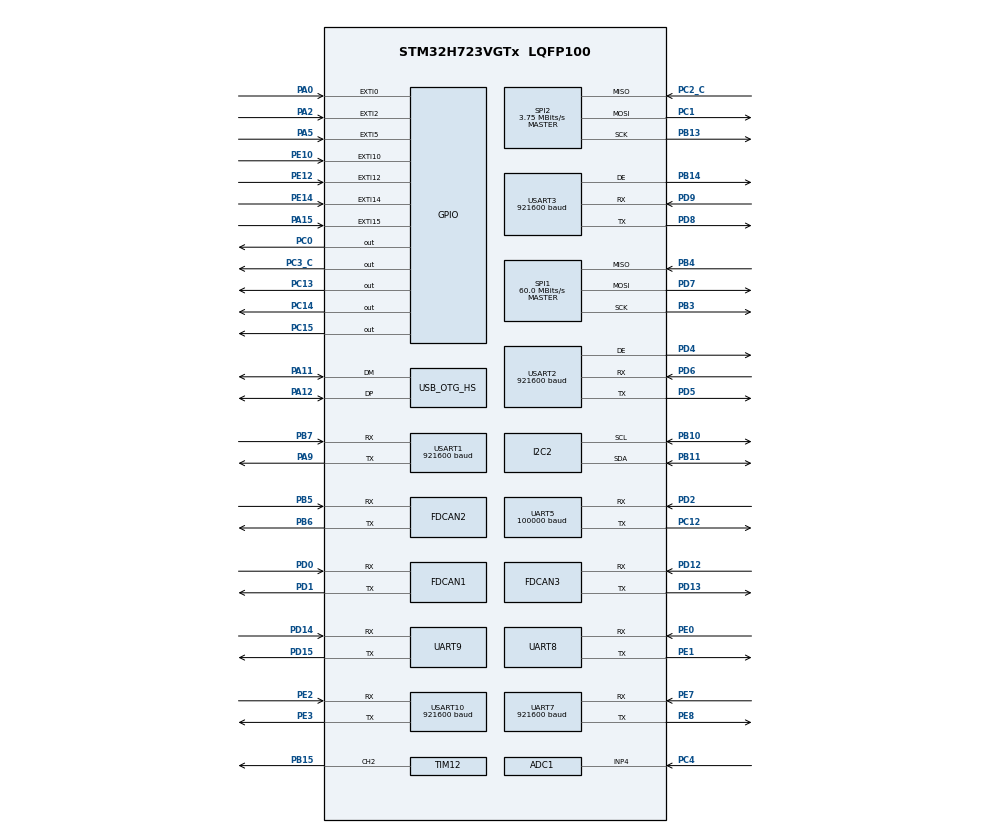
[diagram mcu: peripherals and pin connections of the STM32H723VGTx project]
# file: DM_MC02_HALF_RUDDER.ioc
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ADC1.Channel-0\#ChannelRegularConversion=ADC_CHANNEL_4
ADC1.ContinuousConvMode=ENABLE
ADC1.NbrOfConversionFlag=1
ADC1.OffsetNumber-0\#ChannelRegularConversion=ADC_OFFSET_NONE
ADC1.OffsetSignedSaturation-0\#ChannelRegularConversion=DISABLE
ADC1.Overrun=ADC_OVR_DATA_OVERWRITTEN
ADC1.Rank-0\#ChannelRegularConversion=1
ADC1.SamplingTime-0\#ChannelRegularConversion=ADC_SAMPLETIME_1CYCLE_5
ADC1.master=1
CORTEX_M7.CPU_DCache=Disabled
CORTEX_M7.CPU_ICache=Enabled
CORTEX_M7.default_mode_Activation=0
Dma.Request0=UART5_RX
Dma.Request1=SPI2_RX
Dma.Request10=USART2_TX
Dma.Request11=USART3_RX
Dma.Request12=USART3_TX
Dma.Request2=SPI2_TX
Dma.Request3=USART10_RX
Dma.Request4=USART10_TX
Dma.Request5=UART7_RX
Dma.Request6=UART7_TX
Dma.Request7=USART1_TX
Dma.Request8=USART1_RX
Dma.Request9=USART2_RX
Dma.SPI2_RX.1.Direction=DMA_PERIPH_TO_MEMORY
Dma.SPI2_RX.1.EventEnable=DISABLE
Dma.SPI2_RX.1.FIFOMode=DMA_FIFOMODE_DISABLE
Dma.SPI2_RX.1.Instance=DMA1_Stream2
Dma.SPI2_RX.1.MemDataAlignment=DMA_MDATAALIGN_BYTE
Dma.SPI2_RX.1.MemInc=DMA_MINC_ENABLE
Dma.SPI2_RX.1.Mode=DMA_NORMAL
Dma.SPI2_RX.1.PeriphDataAlignment=DMA_PDATAALIGN_BYTE
Dma.SPI2_RX.1.PeriphInc=DMA_PINC_DISABLE
Dma.SPI2_RX.1.Polarity=HAL_DMAMUX_REQ_GEN_RISING
Dma.SPI2_RX.1.Priority=DMA_PRIORITY_LOW
Dma.SPI2_RX.1.RequestNumber=1
Dma.SPI2_RX.1.SignalID=NONE
Dma.SPI2_RX.1.SyncEnable=DISABLE
Dma.SPI2_RX.1.SyncPolarity=HAL_DMAMUX_SYNC_NO_EVENT
Dma.SPI2_RX.1.SyncRequestNumber=1
Dma.SPI2_RX.1.SyncSignalID=NONE
Dma.SPI2_TX.2.Direction=DMA_MEMORY_TO_PERIPH
Dma.SPI2_TX.2.EventEnable=DISABLE
Dma.SPI2_TX.2.FIFOMode=DMA_FIFOMODE_DISABLE
Dma.SPI2_TX.2.Instance=DMA1_Stream3
Dma.SPI2_TX.2.MemDataAlignment=DMA_MDATAALIGN_BYTE
Dma.SPI2_TX.2.MemInc=DMA_MINC_ENABLE
Dma.SPI2_TX.2.Mode=DMA_NORMAL
Dma.SPI2_TX.2.PeriphDataAlignment=DMA_PDATAALIGN_BYTE
Dma.SPI2_TX.2.PeriphInc=DMA_PINC_DISABLE
Dma.SPI2_TX.2.Polarity=HAL_DMAMUX_REQ_GEN_RISING
Dma.SPI2_TX.2.Priority=DMA_PRIORITY_LOW
Dma.SPI2_TX.2.RequestNumber=1
Dma.SPI2_TX.2.SignalID=NONE
Dma.SPI2_TX.2.SyncEnable=DISABLE
Dma.SPI2_TX.2.SyncPolarity=HAL_DMAMUX_SYNC_NO_EVENT
Dma.SPI2_TX.2.SyncRequestNumber=1
Dma.SPI2_TX.2.SyncSignalID=NONE
Dma.UART5_RX.0.Direction=DMA_PERIPH_TO_MEMORY
Dma.UART5_RX.0.EventEnable=DISABLE
Dma.UART5_RX.0.FIFOMode=DMA_FIFOMODE_DISABLE
Dma.UART5_RX.0.Instance=DMA1_Stream1
Dma.UART5_RX.0.MemDataAlignment=DMA_MDATAALIGN_BYTE
Dma.UART5_RX.0.MemInc=DMA_MINC_ENABLE
Dma.UART5_RX.0.Mode=DMA_NORMAL
Dma.UART5_RX.0.PeriphDataAlignment=DMA_PDATAALIGN_BYTE
Dma.UART5_RX.0.PeriphInc=DMA_PINC_DISABLE
Dma.UART5_RX.0.Polarity=HAL_DMAMUX_REQ_GEN_RISING
Dma.UART5_RX.0.Priority=DMA_PRIORITY_LOW
Dma.UART5_RX.0.RequestNumber=1
Dma.UART5_RX.0.SignalID=NONE
Dma.UART5_RX.0.SyncEnable=DISABLE
Dma.UART5_RX.0.SyncPolarity=HAL_DMAMUX_SYNC_NO_EVENT
Dma.UART5_RX.0.SyncRequestNumber=1
Dma.UART5_RX.0.SyncSignalID=NONE
Dma.UART7_RX.5.Direction=DMA_PERIPH_TO_MEMORY
Dma.UART7_RX.5.EventEnable=DISABLE
Dma.UART7_RX.5.FIFOMode=DMA_FIFOMODE_DISABLE
Dma.UART7_RX.5.Instance=DMA1_Stream7
Dma.UART7_RX.5.MemDataAlignment=DMA_MDATAALIGN_BYTE
Dma.UART7_RX.5.MemInc=DMA_MINC_ENABLE
Dma.UART7_RX.5.Mode=DMA_NORMAL
Dma.UART7_RX.5.PeriphDataAlignment=DMA_PDATAALIGN_BYTE
Dma.UART7_RX.5.PeriphInc=DMA_PINC_DISABLE
Dma.UART7_RX.5.Polarity=HAL_DMAMUX_REQ_GEN_RISING
Dma.UART7_RX.5.Priority=DMA_PRIORITY_LOW
Dma.UART7_RX.5.RequestNumber=1
Dma.UART7_RX.5.SignalID=NONE
Dma.UART7_RX.5.SyncEnable=DISABLE
Dma.UART7_RX.5.SyncPolarity=HAL_DMAMUX_SYNC_NO_EVENT
Dma.UART7_RX.5.SyncRequestNumber=1
Dma.UART7_RX.5.SyncSignalID=NONE
Dma.UART7_TX.6.Direction=DMA_MEMORY_TO_PERIPH
Dma.UART7_TX.6.EventEnable=DISABLE
Dma.UART7_TX.6.FIFOMode=DMA_FIFOMODE_DISABLE
Dma.UART7_TX.6.Instance=DMA2_Stream0
Dma.UART7_TX.6.MemDataAlignment=DMA_MDATAALIGN_BYTE
Dma.UART7_TX.6.MemInc=DMA_MINC_ENABLE
Dma.UART7_TX.6.Mode=DMA_NORMAL
Dma.UART7_TX.6.PeriphDataAlignment=DMA_PDATAALIGN_BYTE
Dma.UART7_TX.6.PeriphInc=DMA_PINC_DISABLE
Dma.UART7_TX.6.Polarity=HAL_DMAMUX_REQ_GEN_RISING
Dma.UART7_TX.6.Priority=DMA_PRIORITY_LOW
Dma.UART7_TX.6.RequestNumber=1
Dma.UART7_TX.6.SignalID=NONE
Dma.UART7_TX.6.SyncEnable=DISABLE
Dma.UART7_TX.6.SyncPolarity=HAL_DMAMUX_SYNC_NO_EVENT
Dma.UART7_TX.6.SyncRequestNumber=1
Dma.UART7_TX.6.SyncSignalID=NONE
Dma.USART10_RX.3.Direction=DMA_PERIPH_TO_MEMORY
Dma.USART10_RX.3.EventEnable=DISABLE
Dma.USART10_RX.3.FIFOMode=DMA_FIFOMODE_DISABLE
Dma.USART10_RX.3.Instance=DMA1_Stream0
Dma.USART10_RX.3.MemDataAlignment=DMA_MDATAALIGN_BYTE
Dma.USART10_RX.3.MemInc=DMA_MINC_ENABLE
Dma.USART10_RX.3.Mode=DMA_NORMAL
Dma.USART10_RX.3.PeriphDataAlignment=DMA_PDATAALIGN_BYTE
Dma.USART10_RX.3.PeriphInc=DMA_PINC_DISABLE
Dma.USART10_RX.3.Polarity=HAL_DMAMUX_REQ_GEN_RISING
Dma.USART10_RX.3.Priority=DMA_PRIORITY_LOW
Dma.USART10_RX.3.RequestNumber=1
Dma.USART10_RX.3.SignalID=NONE
Dma.USART10_RX.3.SyncEnable=DISABLE
Dma.USART10_RX.3.SyncPolarity=HAL_DMAMUX_SYNC_NO_EVENT
Dma.USART10_RX.3.SyncRequestNumber=1
Dma.USART10_RX.3.SyncSignalID=NONE
Dma.USART10_TX.4.Direction=DMA_MEMORY_TO_PERIPH
Dma.USART10_TX.4.EventEnable=DISABLE
Dma.USART10_TX.4.FIFOMode=DMA_FIFOMODE_DISABLE
Dma.USART10_TX.4.Instance=DMA1_Stream4
Dma.USART10_TX.4.MemDataAlignment=DMA_MDATAALIGN_BYTE
Dma.USART10_TX.4.MemInc=DMA_MINC_ENABLE
Dma.USART10_TX.4.Mode=DMA_NORMAL
Dma.USART10_TX.4.PeriphDataAlignment=DMA_PDATAALIGN_BYTE
Dma.USART10_TX.4.PeriphInc=DMA_PINC_DISABLE
Dma.USART10_TX.4.Polarity=HAL_DMAMUX_REQ_GEN_RISING
Dma.USART10_TX.4.Priority=DMA_PRIORITY_LOW
Dma.USART10_TX.4.RequestNumber=1
Dma.USART10_TX.4.SignalID=NONE
Dma.USART10_TX.4.SyncEnable=DISABLE
Dma.USART10_TX.4.SyncPolarity=HAL_DMAMUX_SYNC_NO_EVENT
Dma.USART10_TX.4.SyncRequestNumber=1
Dma.USART10_TX.4.SyncSignalID=NONE
Dma.USART1_RX.8.Direction=DMA_PERIPH_TO_MEMORY
Dma.USART1_RX.8.EventEnable=DISABLE
Dma.USART1_RX.8.FIFOMode=DMA_FIFOMODE_DISABLE
Dma.USART1_RX.8.Instance=DMA1_Stream6
Dma.USART1_RX.8.MemDataAlignment=DMA_MDATAALIGN_BYTE
Dma.USART1_RX.8.MemInc=DMA_MINC_ENABLE
Dma.USART1_RX.8.Mode=DMA_NORMAL
Dma.USART1_RX.8.PeriphDataAlignment=DMA_PDATAALIGN_BYTE
Dma.USART1_RX.8.PeriphInc=DMA_PINC_DISABLE
Dma.USART1_RX.8.Polarity=HAL_DMAMUX_REQ_GEN_RISING
Dma.USART1_RX.8.Priority=DMA_PRIORITY_LOW
Dma.USART1_RX.8.RequestNumber=1
Dma.USART1_RX.8.SignalID=NONE
Dma.USART1_RX.8.SyncEnable=DISABLE
Dma.USART1_RX.8.SyncPolarity=HAL_DMAMUX_SYNC_NO_EVENT
Dma.USART1_RX.8.SyncRequestNumber=1
Dma.USART1_RX.8.SyncSignalID=NONE
Dma.USART1_TX.7.Direction=DMA_MEMORY_TO_PERIPH
Dma.USART1_TX.7.EventEnable=DISABLE
Dma.USART1_TX.7.FIFOMode=DMA_FIFOMODE_DISABLE
Dma.USART1_TX.7.Instance=DMA1_Stream5
Dma.USART1_TX.7.MemDataAlignment=DMA_MDATAALIGN_BYTE
Dma.USART1_TX.7.MemInc=DMA_MINC_ENABLE
Dma.USART1_TX.7.Mode=DMA_NORMAL
Dma.USART1_TX.7.PeriphDataAlignment=DMA_PDATAALIGN_BYTE
Dma.USART1_TX.7.PeriphInc=DMA_PINC_DISABLE
Dma.USART1_TX.7.Polarity=HAL_DMAMUX_REQ_GEN_RISING
Dma.USART1_TX.7.Priority=DMA_PRIORITY_LOW
Dma.USART1_TX.7.RequestNumber=1
Dma.USART1_TX.7.SignalID=NONE
Dma.USART1_TX.7.SyncEnable=DISABLE
Dma.USART1_TX.7.SyncPolarity=HAL_DMAMUX_SYNC_NO_EVENT
Dma.USART1_TX.7.SyncRequestNumber=1
Dma.USART1_TX.7.SyncSignalID=NONE
Dma.USART2_RX.9.Direction=DMA_PERIPH_TO_MEMORY
Dma.USART2_RX.9.EventEnable=DISABLE
Dma.USART2_RX.9.FIFOMode=DMA_FIFOMODE_DISABLE
Dma.USART2_RX.9.Instance=DMA2_Stream1
Dma.USART2_RX.9.MemDataAlignment=DMA_MDATAALIGN_BYTE
Dma.USART2_RX.9.MemInc=DMA_MINC_ENABLE
Dma.USART2_RX.9.Mode=DMA_NORMAL
Dma.USART2_RX.9.PeriphDataAlignment=DMA_PDATAALIGN_BYTE
Dma.USART2_RX.9.PeriphInc=DMA_PINC_DISABLE
Dma.USART2_RX.9.Polarity=HAL_DMAMUX_REQ_GEN_RISING
Dma.USART2_RX.9.Priority=DMA_PRIORITY_LOW
Dma.USART2_RX.9.RequestNumber=1
Dma.USART2_RX.9.SignalID=NONE
Dma.USART2_RX.9.SyncEnable=DISABLE
Dma.USART2_RX.9.SyncPolarity=HAL_DMAMUX_SYNC_NO_EVENT
Dma.USART2_RX.9.SyncRequestNumber=1
Dma.USART2_RX.9.SyncSignalID=NONE
Dma.USART2_TX.10.Direction=DMA_MEMORY_TO_PERIPH
Dma.USART2_TX.10.EventEnable=DISABLE
Dma.USART2_TX.10.FIFOMode=DMA_FIFOMODE_DISABLE
Dma.USART2_TX.10.Instance=DMA2_Stream2
Dma.USART2_TX.10.MemDataAlignment=DMA_MDATAALIGN_BYTE
Dma.USART2_TX.10.MemInc=DMA_MINC_ENABLE
Dma.USART2_TX.10.Mode=DMA_NORMAL
Dma.USART2_TX.10.PeriphDataAlignment=DMA_PDATAALIGN_BYTE
Dma.USART2_TX.10.PeriphInc=DMA_PINC_DISABLE
Dma.USART2_TX.10.Polarity=HAL_DMAMUX_REQ_GEN_RISING
Dma.USART2_TX.10.Priority=DMA_PRIORITY_LOW
Dma.USART2_TX.10.RequestNumber=1
Dma.USART2_TX.10.SignalID=NONE
Dma.USART2_TX.10.SyncEnable=DISABLE
Dma.USART2_TX.10.SyncPolarity=HAL_DMAMUX_SYNC_NO_EVENT
Dma.USART2_TX.10.SyncRequestNumber=1
Dma.USART2_TX.10.SyncSignalID=NONE
Dma.USART3_RX.11.Direction=DMA_PERIPH_TO_MEMORY
Dma.USART3_RX.11.EventEnable=DISABLE
Dma.USART3_RX.11.FIFOMode=DMA_FIFOMODE_DISABLE
Dma.USART3_RX.11.Instance=DMA2_Stream3
Dma.USART3_RX.11.MemDataAlignment=DMA_MDATAALIGN_BYTE
Dma.USART3_RX.11.MemInc=DMA_MINC_ENABLE
Dma.USART3_RX.11.Mode=DMA_NORMAL
Dma.USART3_RX.11.PeriphDataAlignment=DMA_PDATAALIGN_BYTE
Dma.USART3_RX.11.PeriphInc=DMA_PINC_DISABLE
Dma.USART3_RX.11.Polarity=HAL_DMAMUX_REQ_GEN_RISING
Dma.USART3_RX.11.Priority=DMA_PRIORITY_LOW
Dma.USART3_RX.11.RequestNumber=1
Dma.USART3_RX.11.SignalID=NONE
Dma.USART3_RX.11.SyncEnable=DISABLE
Dma.USART3_RX.11.SyncPolarity=HAL_DMAMUX_SYNC_NO_EVENT
Dma.USART3_RX.11.SyncRequestNumber=1
Dma.USART3_RX.11.SyncSignalID=NONE
Dma.USART3_TX.12.Direction=DMA_MEMORY_TO_PERIPH
Dma.USART3_TX.12.EventEnable=DISABLE
Dma.USART3_TX.12.FIFOMode=DMA_FIFOMODE_DISABLE
Dma.USART3_TX.12.Instance=DMA2_Stream4
Dma.USART3_TX.12.MemDataAlignment=DMA_MDATAALIGN_BYTE
Dma.USART3_TX.12.MemInc=DMA_MINC_ENABLE
Dma.USART3_TX.12.Mode=DMA_NORMAL
Dma.USART3_TX.12.PeriphDataAlignment=DMA_PDATAALIGN_BYTE
Dma.USART3_TX.12.PeriphInc=DMA_PINC_DISABLE
Dma.USART3_TX.12.Polarity=HAL_DMAMUX_REQ_GEN_RISING
Dma.USART3_TX.12.Priority=DMA_PRIORITY_LOW
Dma.USART3_TX.12.RequestNumber=1
Dma.USART3_TX.12.SignalID=NONE
Dma.USART3_TX.12.SyncEnable=DISABLE
Dma.USART3_TX.12.SyncPolarity=HAL_DMAMUX_SYNC_NO_EVENT
Dma.USART3_TX.12.SyncRequestNumber=1
Dma.USART3_TX.12.SyncSignalID=NONE
FDCAN1.AutoRetransmission=ENABLE
FDCAN1.CalculateBaudRateNominal=1000000
FDCAN1.CalculateTimeBitNominal=1000
FDCAN1.CalculateTimeQuantumNominal=100.0
FDCAN1.DataTimeSeg1=12
FDCAN1.DataTimeSeg2=2
FDCAN1.ExtFiltersNbr=0
FDCAN1.FrameFormat=FDCAN_FRAME_FD_BRS
FDCAN1.Mode=FDCAN_MODE_NORMAL
FDCAN1.NominalPrescaler=12
FDCAN1.NominalTimeSeg1=7
FDCAN1.NominalTimeSeg2=2
FDCAN1.ProtocolException=ENABLE
FDCAN1.RxBufferSize=FDCAN_DATA_BYTES_64
FDCAN1.RxBuffersNbr=0
FDCAN1.RxFifo0ElmtSize=FDCAN_DATA_BYTES_64
FDCAN1.RxFifo0ElmtsNbr=8
FDCAN1.RxFifo1ElmtSize=FDCAN_DATA_BYTES_64
FDCAN1.RxFifo1ElmtsNbr=0
FDCAN1.StdFiltersNbr=0
FDCAN1.TxBuffersNbr=0
FDCAN1.TxElmtSize=FDCAN_DATA_BYTES_64
FDCAN1.TxEventsNbr=32
FDCAN1.TxFifoQueueElmtsNbr=32
FDCAN2.AutoRetransmission=ENABLE
FDCAN2.CalculateBaudRateNominal=1000000
FDCAN2.CalculateTimeBitNominal=1000
FDCAN2.CalculateTimeQuantumNominal=100.0
FDCAN2.DataTimeSeg1=12
FDCAN2.DataTimeSeg2=2
FDCAN2.ExtFiltersNbr=0
FDCAN2.FrameFormat=FDCAN_FRAME_FD_BRS
FDCAN2.MessageRAMOffset=784
FDCAN2.NominalPrescaler=12
FDCAN2.NominalTimeSeg1=7
FDCAN2.NominalTimeSeg2=2
FDCAN2.ProtocolException=ENABLE
FDCAN2.RxBufferSize=FDCAN_DATA_BYTES_64
FDCAN2.RxFifo0ElmtSize=FDCAN_DATA_BYTES_64
FDCAN2.RxFifo0ElmtsNbr=8
FDCAN2.RxFifo1ElmtSize=FDCAN_DATA_BYTES_64
FDCAN2.RxFifo1ElmtsNbr=0
FDCAN2.StdFiltersNbr=0
FDCAN2.TxBuffersNbr=0
FDCAN2.TxElmtSize=FDCAN_DATA_BYTES_64
FDCAN2.TxEventsNbr=32
FDCAN2.TxFifoQueueElmtsNbr=32
FDCAN3.AutoRetransmission=ENABLE
FDCAN3.CalculateBaudRateNominal=1000000
FDCAN3.CalculateTimeBitNominal=1000
FDCAN3.CalculateTimeQuantumNominal=100.0
FDCAN3.DataPrescaler=1
FDCAN3.DataTimeSeg1=12
FDCAN3.DataTimeSeg2=2
FDCAN3.ExtFiltersNbr=0
FDCAN3.FrameFormat=FDCAN_FRAME_FD_BRS
FDCAN3.MessageRAMOffset=1568
FDCAN3.NominalPrescaler=12
FDCAN3.NominalTimeSeg1=7
FDCAN3.NominalTimeSeg2=2
FDCAN3.ProtocolException=ENABLE
FDCAN3.RxBufferSize=FDCAN_DATA_BYTES_64
FDCAN3.RxFifo0ElmtSize=FDCAN_DATA_BYTES_64
FDCAN3.RxFifo0ElmtsNbr=8
FDCAN3.RxFifo1ElmtSize=FDCAN_DATA_BYTES_64
FDCAN3.RxFifo1ElmtsNbr=0
FDCAN3.StdFiltersNbr=0
FDCAN3.TxBuffersNbr=0
FDCAN3.TxElmtSize=FDCAN_DATA_BYTES_64
FDCAN3.TxEventsNbr=32
FDCAN3.TxFifoQueueElmtsNbr=32
FREERTOS.INCLUDE_eTaskGetState=1
FREERTOS.INCLUDE_pcTaskGetTaskName=1
FREERTOS.INCLUDE_uxTaskGetStackHighWaterMark=1
FREERTOS.INCLUDE_uxTaskGetStackHighWaterMark2=1
FREERTOS.INCLUDE_vTaskCleanUpResources=1
FREERTOS.INCLUDE_vTaskDelayUntil=1
FREERTOS.INCLUDE_xQueueGetMutexHolder=1
FREERTOS.INCLUDE_xSemaphoreGetMutexHolder=1
FREERTOS.INCLUDE_xTaskAbortDelay=1
FREERTOS.INCLUDE_xTaskGetCurrentTaskHandle=1
FREERTOS.INCLUDE_xTaskGetHandle=1
FREERTOS.MEMORY_ALLOCATION=1
FREERTOS.Tasks01=defaultTask,-3,128,StartDefaultTask,Default,NULL,Static,defaultTaskBuffer,defaultTaskControlBlock
FREERTOS.configCHECK_FOR_STACK_OVERFLOW=2
FREERTOS.configENABLE_BACKWARD_COMPATIBILITY=0
FREERTOS.configENABLE_FPU=1
FREERTOS.configGENERATE_RUN_TIME_STATS=1
FREERTOS.configRECORD_STACK_HIGH_ADDRESS=1
FREERTOS.configUSE_APPLICATION_TASK_TAG=1
FREERTOS.configUSE_COUNTING_SEMAPHORES=1
FREERTOS.configUSE_IDLE_HOOK=1
FREERTOS.configUSE_RECURSIVE_MUTEXES=1
FREERTOS.configUSE_TICK_HOOK=1
FREERTOS.configUSE_TRACE_FACILITY=1
I2C2.Timing=0x307075B1
Mcu.Family=STM32H7
Mcu.Name=STM32H723VGTx
Mcu.Package=LQFP100
NVIC.DMA1_Stream0_IRQn=true\:5\:0\:false\:false\:true\:true\:false\:true\:true
NVIC.DMA1_Stream1_IRQn=true\:5\:0\:false\:false\:true\:true\:false\:true\:true
NVIC.DMA1_Stream2_IRQn=true\:5\:0\:false\:false\:true\:true\:false\:true\:true
NVIC.DMA1_Stream3_IRQn=true\:5\:0\:false\:false\:true\:true\:false\:true\:true
NVIC.DMA1_Stream4_IRQn=true\:5\:0\:false\:false\:true\:true\:false\:true\:true
NVIC.DMA1_Stream5_IRQn=true\:5\:0\:false\:false\:true\:true\:false\:true\:true
NVIC.DMA1_Stream6_IRQn=true\:5\:0\:false\:false\:true\:true\:false\:true\:true
NVIC.DMA1_Stream7_IRQn=true\:5\:0\:false\:false\:true\:true\:false\:true\:true
NVIC.DMA2_Stream0_IRQn=true\:5\:0\:false\:false\:true\:true\:false\:true\:true
NVIC.DMA2_Stream1_IRQn=true\:5\:0\:false\:false\:true\:true\:false\:true\:true
NVIC.DMA2_Stream2_IRQn=true\:5\:0\:false\:false\:true\:true\:false\:true\:true
NVIC.DMA2_Stream3_IRQn=true\:5\:0\:false\:false\:true\:true\:false\:true\:true
NVIC.DMA2_Stream4_IRQn=true\:5\:0\:false\:false\:true\:true\:false\:true\:true
NVIC.EXTI0_IRQn=true\:5\:0\:false\:false\:true\:true\:true\:true\:true
NVIC.EXTI15_10_IRQn=true\:5\:0\:false\:false\:true\:true\:true\:true\:true
NVIC.EXTI2_IRQn=true\:5\:0\:false\:false\:true\:true\:true\:true\:true
NVIC.EXTI9_5_IRQn=true\:5\:0\:false\:false\:true\:true\:true\:true\:true
NVIC.FDCAN1_IT0_IRQn=true\:5\:0\:false\:false\:true\:true\:true\:true\:true
NVIC.FDCAN1_IT1_IRQn=true\:5\:0\:false\:false\:true\:true\:true\:true\:true
NVIC.FDCAN2_IT0_IRQn=true\:5\:0\:false\:false\:true\:true\:true\:true\:true
NVIC.FDCAN2_IT1_IRQn=true\:5\:0\:false\:false\:true\:true\:true\:true\:true
NVIC.FDCAN3_IT0_IRQn=true\:5\:0\:false\:false\:true\:true\:true\:true\:true
NVIC.FDCAN3_IT1_IRQn=true\:5\:0\:false\:false\:true\:true\:true\:true\:true
NVIC.OTG_HS_EP1_IN_IRQn=true\:5\:0\:false\:false\:true\:true\:true\:true\:true
NVIC.OTG_HS_EP1_OUT_IRQn=true\:5\:0\:false\:false\:true\:true\:true\:true\:true
NVIC.OTG_HS_IRQn=true\:5\:0\:false\:false\:true\:true\:true\:true\:true
NVIC.PriorityGroup=NVIC_PRIORITYGROUP_4
NVIC.SPI2_IRQn=true\:5\:0\:false\:false\:true\:true\:false\:true\:true
NVIC.TIM23_IRQn=true\:15\:0\:false\:false\:true\:false\:false\:true\:true
NVIC.TimeBase=TIM23_IRQn
NVIC.TimeBaseIP=TIM23
NVIC.UART5_IRQn=true\:5\:0\:false\:false\:true\:true\:false\:true\:true
NVIC.UART7_IRQn=true\:5\:0\:false\:false\:true\:true\:true\:true\:true
NVIC.USART10_IRQn=true\:5\:0\:false\:false\:true\:true\:true\:true\:true
NVIC.USART1_IRQn=true\:5\:0\:false\:false\:true\:true\:true\:true\:true
NVIC.USART2_IRQn=true\:5\:0\:false\:false\:true\:true\:true\:true\:true
NVIC.USART3_IRQn=true\:5\:0\:false\:false\:true\:true\:true\:true\:true
PA0.Signal=GPXTI0
PA11.Mode=Device_Only_FS
PA11.Signal=USB_OTG_HS_DM
PA12.Mode=Device_Only_FS
PA12.Signal=USB_OTG_HS_DP
PA13(JTMS/SWDIO).Mode=Serial_Wire
PA13(JTMS/SWDIO).Signal=DEBUG_JTMS-SWDIO
PA14(JTCK/SWCLK).Mode=Serial_Wire
PA14(JTCK/SWCLK).Signal=DEBUG_JTCK-SWCLK
PA15(JTDI).Signal=GPXTI15
PA2.Signal=GPXTI2
PA5.Signal=GPXTI5
PA9.Mode=Asynchronous
PA9.Signal=USART1_TX
PB10.Mode=I2C
PB10.Signal=I2C2_SCL
PB11.Mode=I2C
PB11.Signal=I2C2_SDA
PB13.GPIO_Speed=GPIO_SPEED_FREQ_VERY_HIGH
PB13.Mode=Full_Duplex_Master
PB13.Signal=SPI2_SCK
PB14.Mode=Hardware Flow Control (RS485)
PB14.Signal=USART3_DE
PB15.Signal=S_TIM12_CH2
PB3(JTDO/TRACESWO).Mode=Full_Duplex_Master
PB3(JTDO/TRACESWO).Signal=SPI1_SCK
PB4(NJTRST).Mode=Full_Duplex_Master
PB4(NJTRST).Signal=SPI1_MISO
PB5.Mode=FDCAN_Activate
PB5.Signal=FDCAN2_RX
PB6.Mode=FDCAN_Activate
PB6.Signal=FDCAN2_TX
PB7.Mode=Asynchronous
PB7.Signal=USART1_RX
PC0.GPIO_Speed=GPIO_SPEED_FREQ_VERY_HIGH
PC0.PinState=GPIO_PIN_SET
PC0.Signal=GPIO_Output
PC1.GPIO_Speed=GPIO_SPEED_FREQ_VERY_HIGH
PC1.Mode=Full_Duplex_Master
PC1.Signal=SPI2_MOSI
PC12.Mode=Asynchronous
PC12.Signal=UART5_TX
PC13.Signal=GPIO_Output
PC14-OSC32_IN.Signal=GPIO_Output
PC15-OSC32_OUT.Signal=GPIO_Output
PC2_C.GPIO_Speed=GPIO_SPEED_FREQ_VERY_HIGH
PC2_C.Mode=Full_Duplex_Master
PC2_C.Signal=SPI2_MISO
PC3_C.GPIO_Speed=GPIO_SPEED_FREQ_VERY_HIGH
PC3_C.PinState=GPIO_PIN_SET
PC3_C.Signal=GPIO_Output
PC4.Signal=ADCx_INP4
PD0.Mode=FDCAN_Activate
PD0.Signal=FDCAN1_RX
PD1.Mode=FDCAN_Activate
PD1.Signal=FDCAN1_TX
PD12.Mode=FDCAN_Activate
PD12.Signal=FDCAN3_RX
PD13.Mode=FDCAN_Activate
PD13.Signal=FDCAN3_TX
PD14.Mode=Asynchronous
PD14.Signal=UART9_RX
PD15.Mode=Asynchronous
PD15.Signal=UART9_TX
PD2.Mode=Asynchronous
PD2.Signal=UART5_RX
PD4.Mode=Hardware Flow Control (RS485)
PD4.Signal=USART2_DE
PD5.Mode=Asynchronous
PD5.Signal=USART2_TX
PD6.Mode=Asynchronous
PD6.Signal=USART2_RX
PD7.Mode=Full_Duplex_Master
PD7.Signal=SPI1_MOSI
PD8.Mode=Asynchronous
PD8.Signal=USART3_TX
PD9.Mode=Asynchronous
PD9.Signal=USART3_RX
PE0.Mode=Asynchronous
PE0.Signal=UART8_RX
PE1.Mode=Asynchronous
PE1.Signal=UART8_TX
PE10.Signal=GPXTI10
PE12.Signal=GPXTI12
PE13.Signal=S_TIM1_CH3
PE14.Signal=GPXTI14
PE2.Mode=Asynchronous
PE2.Signal=USART10_RX
PE3.Mode=Asynchronous
PE3.Signal=USART10_TX
PE7.Mode=Asynchronous
PE7.Signal=UART7_RX
PE8.Mode=Asynchronous
PE8.Signal=UART7_TX
PE9.Signal=S_TIM1_CH1
PH0-OSC_IN.Mode=HSE-External-Oscillator
PH0-OSC_IN.Signal=RCC_OSC_IN
PH1-OSC_OUT.Mode=HSE-External-Oscillator
PH1-OSC_OUT.Signal=RCC_OSC_OUT
ProjectManager.HeapSize=0x200
ProjectManager.StackSize=0x400
ProjectManager.TargetToolchain=CMake
RCC.ADCFreq_Value=96000000
RCC.APB1Freq_Value=120000000
RCC.APB2Freq_Value=120000000
RCC.APB3Freq_Value=120000000
RCC.APB4Freq_Value=120000000
RCC.CortexFreq_Value=480000000
RCC.D1PPRE=RCC_APB3_DIV2
RCC.D2PPRE1=RCC_APB1_DIV2
RCC.D2PPRE2=RCC_APB2_DIV2
RCC.D3PPRE=RCC_APB4_DIV2
RCC.DIVM1=2
RCC.DIVM2=2
RCC.DIVM3=2
RCC.DIVN1=40
RCC.DIVN2=16
RCC.DIVN3=16
RCC.DIVP1=1
RCC.DIVQ1=4
RCC.DIVQ3=4
RCC.HCLKFreq_Value=240000000
RCC.HPRE=RCC_HCLK_DIV2
RCC.HSE_VALUE=24000000
RCC.PLL1_VCO_SEL-AdvancedSettings=RCC_PLL1VCOMEDIUM
RCC.PLL2FRACN=0
RCC.PLL3FRACN=0
RCC.PLL3_VCI_Range-AdvancedSettings=RCC_PLL3VCIRANGE_3
RCC.PLL3_VCO_SEL-AdvancedSettings=RCC_PLL3VCOMEDIUM
RCC.PLLFRACN=0
RCC.PLLSourceVirtual=RCC_PLLSOURCE_HSE
RCC.SYSCLKFreq_VALUE=480000000
RCC.SYSCLKSource=RCC_SYSCLKSOURCE_PLLCLK
RCC.USBCLockSelection=RCC_USBCLKSOURCE_PLL3
RCC.USBFreq_Value=48000000
SH.ADCx_INP4.0=ADC1_INP4,IN4-Single-Ended
SH.S_TIM12_CH2.0=TIM12_CH2,PWM Generation2 CH2
SH.S_TIM1_CH1.0=TIM1_CH1
SH.S_TIM1_CH3.0=TIM1_CH3
SPI1.CalculateBaudRate=60.0 MBits/s
SPI1.Direction=SPI_DIRECTION_2LINES
SPI1.Mode=SPI_MODE_MASTER
SPI1.VirtualType=VM_MASTER
SPI2.BaudRatePrescaler=SPI_BAUDRATEPRESCALER_32
SPI2.CLKPhase=SPI_PHASE_2EDGE
SPI2.CLKPolarity=SPI_POLARITY_HIGH
SPI2.CalculateBaudRate=3.75 MBits/s
SPI2.DataSize=SPI_DATASIZE_8BIT
SPI2.Direction=SPI_DIRECTION_2LINES
SPI2.Mode=SPI_MODE_MASTER
SPI2.NSSPMode=SPI_NSS_PULSE_DISABLE
SPI2.VirtualType=VM_MASTER
TIM12.Channel-PWM\ Generation2\ CH2=TIM_CHANNEL_2
TIM12.Period=60000
TIM12.Prescaler=1-1
TIM2.Period=60000
TIM2.Prescaler=80-1
UART5.BaudRate=100000
UART5.Mode=MODE_RX
UART5.Parity=PARITY_EVEN
UART5.StopBits=UART_STOPBITS_2
UART5.WordLength=WORDLENGTH_9B
UART7.BaudRate=921600
USART1.BaudRate=921600
USART1.Mode=MODE_TX_RX
USART1.VirtualMode-Asynchronous=VM_ASYNC
USART10.BaudRate=921600
USART10.VirtualMode=VM_ASYNC
USART2.BaudRate=921600
USART2.VirtualMode-Asynchronous=VM_ASYNC
USART2.VirtualMode-Hardware\ Flow\ Control\ (RS485)=VM_ASYNC
USART3.BaudRate=921600
USART3.VirtualMode-Asynchronous=VM_ASYNC
USART3.VirtualMode-Hardware\ Flow\ Control\ (RS485)=VM_ASYNC
USB_DEVICE.CLASS_NAME_HS=CDC
USB_DEVICE.PRODUCT_STRING_CDC_HS=BetaRobot_VCP
USB_DEVICE.USBD_LPM_ENABLED=0
USB_DEVICE.VirtualMode=Cdc
USB_DEVICE.VirtualModeHS=Cdc_HS
USB_OTG_HS.VirtualMode-Device_Only_FS=Device_Only_FS
USB_OTG_HS.dma_enable-Device_Only_FS=DISABLE
VP_FREERTOS_VS_CMSIS_V1.Mode=CMSIS_V1
VP_MEMORYMAP_VS_MEMORYMAP.Mode=CurAppReg
VP_SYS_VS_tim23.Mode=TIM23
VP_TIM12_VS_ClockSourceINT.Mode=Internal
VP_TIM1_VS_ClockSourceINT.Mode=Internal
VP_TIM2_VS_ClockSourceINT.Mode=Internal
VP_USB_DEVICE_VS_USB_DEVICE_CDC_HS.Mode=CDC_HS
board=custom

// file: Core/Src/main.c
/* USER CODE BEGIN Header */
/**
  ******************************************************************************
  * @file           : main.c
  * @brief          : Main program body
  ******************************************************************************
  * @attention
  *
  * Copyright (c) 2026 STMicroelectronics.
  * All rights reserved.
  *
  * This software is licensed under terms that can be found in the LICENSE file
  * in the root directory of this software component.
  * If no LICENSE file comes with this software, it is provided AS-IS.
  *
  ******************************************************************************
  */
/* USER CODE END Header */
#include "main.h"
#include "cmsis_os.h"
#include "adc.h"
#include "dma.h"
#include "fdcan.h"
#include "i2c.h"
#include "spi.h"
#include "tim.h"
#include "usart.h"
#include "usb_device.h"
#include "gpio.h"

/* USER CODE BEGIN Includes */
#include "app.h"
#include "bsp_tim.h"
/* USER CODE END Includes */

void SystemClock_Config(void);
void MX_FREERTOS_Init(void);

int main(void)
{

  /* Enable the CPU Cache */

  /* Enable I-Cache---------------------------------------------------------*/
  SCB_EnableICache();

  /* MCU Configuration--------------------------------------------------------*/

  /* Reset of all peripherals, Initializes the Flash interface and the Systick. */
  HAL_Init();

  /* Configure the system clock */
  SystemClock_Config();

  /* Initialize all configured peripherals */
  MX_GPIO_Init();
  MX_DMA_Init();
  MX_ADC1_Init();
  MX_TIM2_Init();
  MX_TIM12_Init();
  MX_UART5_Init();
  MX_SPI2_Init();
  MX_FDCAN1_Init();
  MX_FDCAN2_Init();
  MX_FDCAN3_Init();
  MX_I2C2_Init();
  MX_SPI1_Init();
  MX_UART7_Init();
  MX_UART8_Init();
  MX_UART9_Init();
  MX_USART1_UART_Init();
  MX_USART2_UART_Init();
  MX_USART3_UART_Init();
  MX_USART10_UART_Init();
  MX_TIM1_Init();
  /* USER CODE BEGIN 2 */
  function_in_main_c();
  /* USER CODE END 2 */

  /* Call init function for freertos objects (in cmsis_os2.c) */
  MX_FREERTOS_Init();

  /* Start scheduler */
  osKernelStart();

  /* We should never get here as control is now taken by the scheduler */

  /* Infinite loop */
  while (1)
  {

  }
}

void SystemClock_Config(void)
{
  RCC_OscInitTypeDef RCC_OscInitStruct = {0};
  RCC_ClkInitTypeDef RCC_ClkInitStruct = {0};

  /** Supply configuration update enable
  */
  HAL_PWREx_ConfigSupply(PWR_LDO_SUPPLY);

  /** Configure the main internal regulator output voltage
  */
  __HAL_PWR_VOLTAGESCALING_CONFIG(PWR_REGULATOR_VOLTAGE_SCALE0);

  while(!__HAL_PWR_GET_FLAG(PWR_FLAG_VOSRDY)) {}

  /** Initializes the RCC Oscillators according to the specified parameters
  * in the RCC_OscInitTypeDef structure.
  */
  RCC_OscInitStruct.OscillatorType = RCC_OSCILLATORTYPE_HSE;
  RCC_OscInitStruct.HSEState = RCC_HSE_ON;
  RCC_OscInitStruct.PLL.PLLState = RCC_PLL_ON;
  RCC_OscInitStruct.PLL.PLLSource = RCC_PLLSOURCE_HSE;
  RCC_OscInitStruct.PLL.PLLM = 2;
  RCC_OscInitStruct.PLL.PLLN = 40;
  RCC_OscInitStruct.PLL.PLLP = 1;
  RCC_OscInitStruct.PLL.PLLQ = 4;
  RCC_OscInitStruct.PLL.PLLR = 2;
  RCC_OscInitStruct.PLL.PLLRGE = RCC_PLL1VCIRANGE_3;
  RCC_OscInitStruct.PLL.PLLVCOSEL = RCC_PLL1VCOWIDE;
  RCC_OscInitStruct.PLL.PLLFRACN = 0;
  if (HAL_RCC_OscConfig(&RCC_OscInitStruct) != HAL_OK)
  {
    Error_Handler();
  }

  /** Initializes the CPU, AHB and APB buses clocks
  */
  RCC_ClkInitStruct.ClockType = RCC_CLOCKTYPE_HCLK|RCC_CLOCKTYPE_SYSCLK
                              |RCC_CLOCKTYPE_PCLK1|RCC_CLOCKTYPE_PCLK2
                              |RCC_CLOCKTYPE_D3PCLK1|RCC_CLOCKTYPE_D1PCLK1;
  RCC_ClkInitStruct.SYSCLKSource = RCC_SYSCLKSOURCE_PLLCLK;
  RCC_ClkInitStruct.SYSCLKDivider = RCC_SYSCLK_DIV1;
  RCC_ClkInitStruct.AHBCLKDivider = RCC_HCLK_DIV2;
  RCC_ClkInitStruct.APB3CLKDivider = RCC_APB3_DIV2;
  RCC_ClkInitStruct.APB1CLKDivider = RCC_APB1_DIV2;
  RCC_ClkInitStruct.APB2CLKDivider = RCC_APB2_DIV2;
  RCC_ClkInitStruct.APB4CLKDivider = RCC_APB4_DIV2;

  if (HAL_RCC_ClockConfig(&RCC_ClkInitStruct, FLASH_LATENCY_3) != HAL_OK)
  {
    Error_Handler();
  }
}

void HAL_TIM_PeriodElapsedCallback(TIM_HandleTypeDef *htim)
{
  if (htim->Instance == TIM23)
  {
    HAL_IncTick();
  }
  /* USER CODE BEGIN Callback 1 */
  BSPTim_PeriodElapsedCallback(htim);
  /* USER CODE END Callback 1 */
}

void Error_Handler(void)
{
  __disable_irq();
  while (1)
  {
  }
}
